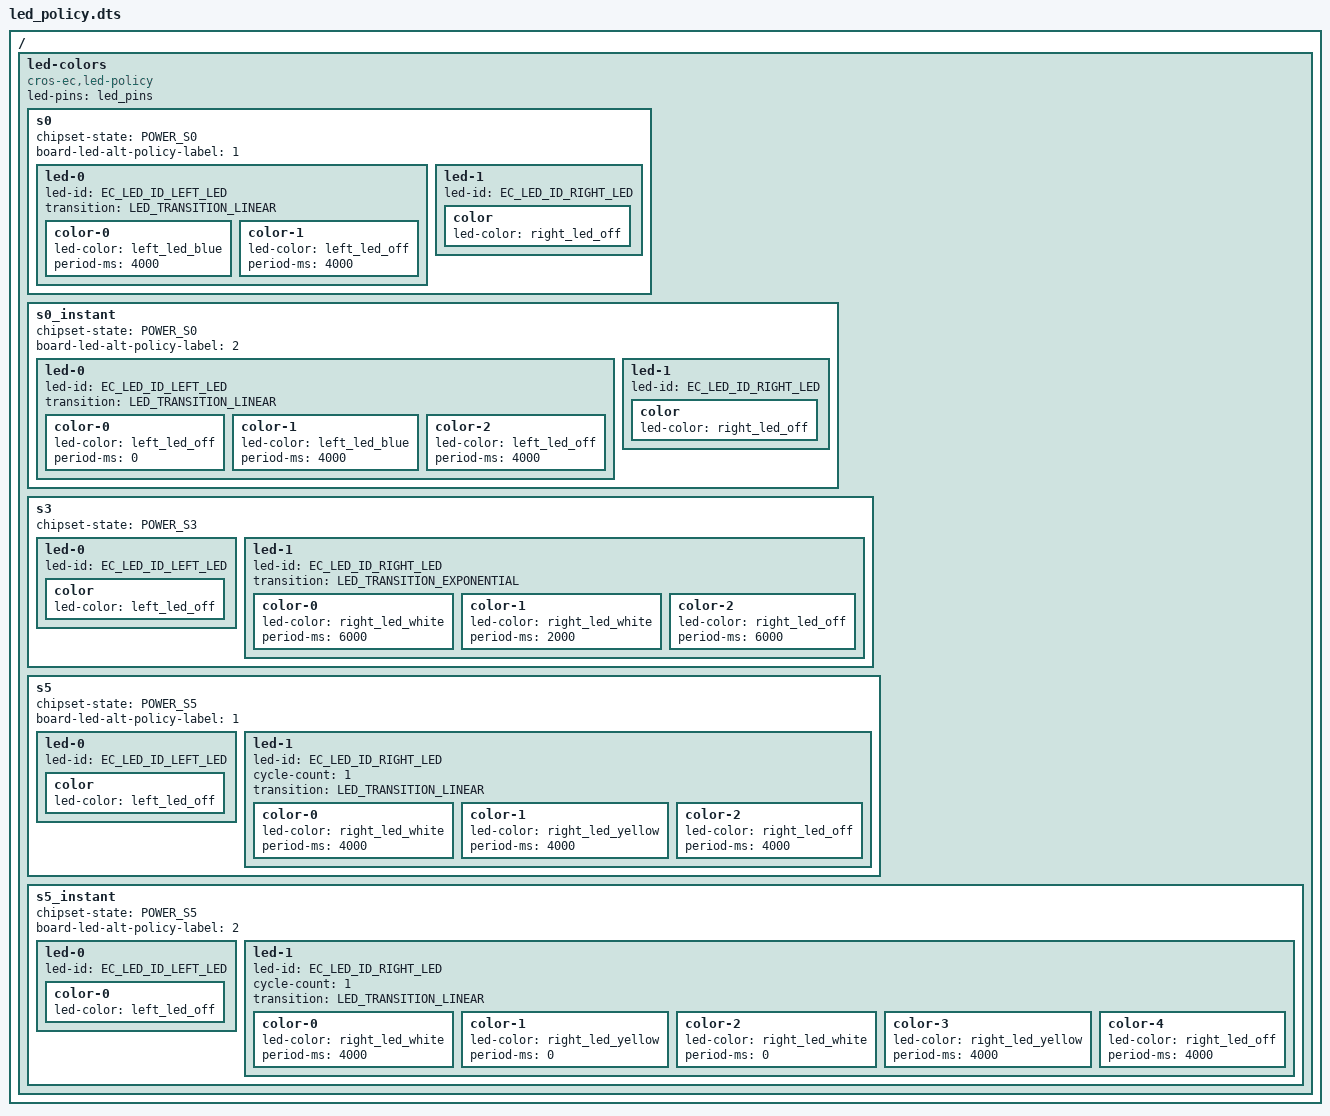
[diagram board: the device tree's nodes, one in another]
/* Copyright 2023 The ChromiumOS Authors
 * Use of this source code is governed by a BSD-style license that can be
 * found in the LICENSE file.
 */

/ {
	led-colors {
		compatible = "cros-ec,led-policy";
		led-pins = <&led_pins>;

		s0 {
			chipset-state = "POWER_S0";
			board-led-alt-policy-label = <1>;

			led-0 {
				led-id = "EC_LED_ID_LEFT_LED";
				transition = "LED_TRANSITION_LINEAR";

				color-0 {
					led-color = <&left_led_blue>;
					period-ms = <4000>;
				};
				color-1 {
					led-color = <&left_led_off>;
					period-ms = <4000>;
				};
			};
			led-1 {
				led-id = "EC_LED_ID_RIGHT_LED";

				color {
					led-color = <&right_led_off>;
				};
			};
		};

		/* Duplicate S0 logic with instant transitions inserted */
		s0_instant {
			chipset-state = "POWER_S0";
			board-led-alt-policy-label = <2>;

			led-0 {
				led-id = "EC_LED_ID_LEFT_LED";
				transition = "LED_TRANSITION_LINEAR";

				color-0 {
					led-color = <&left_led_off>;
					period-ms = <0>; /* Instant transition */
				};
				color-1 {
					led-color = <&left_led_blue>;
					period-ms = <4000>;
				};
				color-2 {
					led-color = <&left_led_off>;
					period-ms = <4000>;
				};
			};
			led-1 {
				led-id = "EC_LED_ID_RIGHT_LED";

				color {
					led-color = <&right_led_off>;
				};
			};
		};

		s3 {
			chipset-state = "POWER_S3";

			led-0 {
				led-id = "EC_LED_ID_LEFT_LED";

				color {
					led-color = <&left_led_off>;
				};
			};
			led-1 {
				led-id = "EC_LED_ID_RIGHT_LED";
				transition = "LED_TRANSITION_EXPONENTIAL";

				color-0 {
					led-color = <&right_led_white>;
					period-ms = <6000>;
				};
				color-1 {
					led-color = <&right_led_white>;
					period-ms = <2000>;
				};
				color-2 {
					led-color = <&right_led_off>;
					period-ms = <6000>;
				};
			};
		};

		s5 {
			chipset-state = "POWER_S5";
			board-led-alt-policy-label = <1>;

			led-0 {
				led-id = "EC_LED_ID_LEFT_LED";

				color {
					led-color = <&left_led_off>;
				};
			};
			led-1 {
				led-id = "EC_LED_ID_RIGHT_LED";
				cycle-count = <1>;
				transition = "LED_TRANSITION_LINEAR";

				color-0 {
					led-color = <&right_led_white>;
					period-ms = <4000>;
				};
				color-1 {
					led-color = <&right_led_yellow>;
					period-ms = <4000>;
				};
				color-2 {
					led-color = <&right_led_off>;
					period-ms = <4000>;
				};
			};
		};

		/* Duplicate S5 logic with instant transitions inserted */
		s5_instant {
			chipset-state = "POWER_S5";
			board-led-alt-policy-label = <2>;

			led-0 {
				led-id = "EC_LED_ID_LEFT_LED";

				color-0 {
					led-color = <&left_led_off>;
				};
			};
			led-1 {
				led-id = "EC_LED_ID_RIGHT_LED";
				cycle-count = <1>;
				transition = "LED_TRANSITION_LINEAR";

				color-0 {
					led-color = <&right_led_white>;
					period-ms = <4000>;
				};
				color-1 {
					led-color = <&right_led_yellow>;
					period-ms = <0>; /* Instant transition */
				};
				color-2 {
					led-color = <&right_led_white>;
					period-ms = <0>; /* Instant transition */
				};
				color-3 {
					led-color = <&right_led_yellow>;
					period-ms = <4000>;
				};
				color-4 {
					led-color = <&right_led_off>;
					period-ms = <4000>;
				};
			};
		};
	};
};
